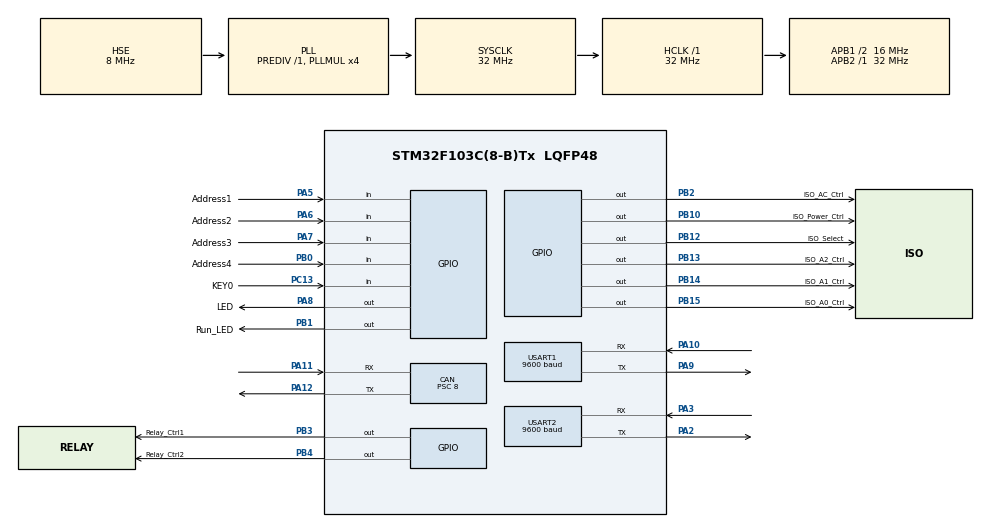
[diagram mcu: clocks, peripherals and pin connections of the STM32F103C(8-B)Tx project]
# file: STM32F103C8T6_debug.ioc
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CAN.AWUM=ENABLE
CAN.BS1=CAN_BS1_6TQ
CAN.CalculateBaudRate=250000
CAN.CalculateTimeBit=4000
CAN.CalculateTimeQuantum=500.0
CAN.NART=ENABLE
CAN.Prescaler=8
Dma.Request0=USART1_RX
Dma.Request1=USART1_TX
Dma.Request2=USART2_TX
Dma.USART1_RX.0.Direction=DMA_PERIPH_TO_MEMORY
Dma.USART1_RX.0.Instance=DMA1_Channel5
Dma.USART1_RX.0.MemDataAlignment=DMA_MDATAALIGN_BYTE
Dma.USART1_RX.0.MemInc=DMA_MINC_ENABLE
Dma.USART1_RX.0.Mode=DMA_NORMAL
Dma.USART1_RX.0.PeriphDataAlignment=DMA_PDATAALIGN_BYTE
Dma.USART1_RX.0.PeriphInc=DMA_PINC_DISABLE
Dma.USART1_RX.0.Priority=DMA_PRIORITY_LOW
Dma.USART1_TX.1.Direction=DMA_MEMORY_TO_PERIPH
Dma.USART1_TX.1.Instance=DMA1_Channel4
Dma.USART1_TX.1.MemDataAlignment=DMA_MDATAALIGN_BYTE
Dma.USART1_TX.1.MemInc=DMA_MINC_ENABLE
Dma.USART1_TX.1.Mode=DMA_NORMAL
Dma.USART1_TX.1.PeriphDataAlignment=DMA_PDATAALIGN_BYTE
Dma.USART1_TX.1.PeriphInc=DMA_PINC_DISABLE
Dma.USART1_TX.1.Priority=DMA_PRIORITY_LOW
Dma.USART2_TX.2.Direction=DMA_MEMORY_TO_PERIPH
Dma.USART2_TX.2.Instance=DMA1_Channel7
Dma.USART2_TX.2.MemDataAlignment=DMA_MDATAALIGN_BYTE
Dma.USART2_TX.2.MemInc=DMA_MINC_ENABLE
Dma.USART2_TX.2.Mode=DMA_NORMAL
Dma.USART2_TX.2.PeriphDataAlignment=DMA_PDATAALIGN_BYTE
Dma.USART2_TX.2.PeriphInc=DMA_PINC_DISABLE
Dma.USART2_TX.2.Priority=DMA_PRIORITY_LOW
FREERTOS.Tasks01=defaultTask,24,128,StartDefaultTask,Default,NULL,Dynamic,NULL,NULL;BSP_Task1,8,128,BSP_Task,As weak,NULL,Dynamic,NULL,NULL;APL_Task1,8,512,APL_Task,As weak,NULL,Dynamic,NULL,NULL;CAN_Task1,8,256,CAN_Task,As weak,NULL,Dynamic,NULL,NULL
FREERTOS.configTOTAL_HEAP_SIZE=5120
IWDG.Prescaler=IWDG_PRESCALER_32
IWDG.Reload=2500
Mcu.Family=STM32F1
Mcu.Name=STM32F103C(8-B)Tx
Mcu.Package=LQFP48
NVIC.DMA1_Channel4_IRQn=true\:5\:0\:false\:false\:true\:true\:false\:true
NVIC.DMA1_Channel5_IRQn=true\:5\:0\:false\:false\:true\:true\:false\:true
NVIC.DMA1_Channel7_IRQn=true\:5\:0\:false\:false\:true\:true\:false\:true
NVIC.PriorityGroup=NVIC_PRIORITYGROUP_4
NVIC.TIM1_UP_IRQn=true\:5\:0\:true\:false\:true\:true\:true\:true
NVIC.USART1_IRQn=true\:5\:0\:false\:false\:true\:true\:true\:true
NVIC.USART2_IRQn=true\:5\:0\:false\:false\:true\:true\:true\:true
NVIC.USB_LP_CAN1_RX0_IRQn=true\:5\:0\:false\:false\:true\:true\:true\:true
PA10.Mode=Asynchronous
PA10.Signal=USART1_RX
PA11.Mode=CAN_Activate
PA11.Signal=CAN_RX
PA12.Mode=CAN_Activate
PA12.Signal=CAN_TX
PA13.Mode=Serial_Wire
PA13.Signal=SYS_JTMS-SWDIO
PA14.Mode=Serial_Wire
PA14.Signal=SYS_JTCK-SWCLK
PA2.Mode=Asynchronous
PA2.Signal=USART2_TX
PA3.Mode=Asynchronous
PA3.Signal=USART2_RX
PA5.GPIO_Label=Address1
PA5.Signal=GPIO_Input
PA6.GPIO_Label=Address2
PA6.Signal=GPIO_Input
PA7.GPIO_Label=Address3
PA7.Signal=GPIO_Input
PA8.GPIO_Label=LED
PA8.Signal=GPIO_Output
PA9.Mode=Asynchronous
PA9.Signal=USART1_TX
PB0.GPIO_Label=Address4
PB0.Signal=GPIO_Input
PB1.GPIO_Label=Run_LED
PB1.Signal=GPIO_Output
PB10.GPIO_Label=ISO_Power_Ctrl
PB10.Signal=GPIO_Output
PB12.GPIO_Label=ISO_Select
PB12.Signal=GPIO_Output
PB13.GPIO_Label=ISO_A2_Ctrl
PB13.Signal=GPIO_Output
PB14.GPIO_Label=ISO_A1_Ctrl
PB14.Signal=GPIO_Output
PB15.GPIO_Label=ISO_A0_Ctrl
PB15.Signal=GPIO_Output
PB2.GPIO_Label=ISO_AC_Ctrl
PB2.Signal=GPIO_Output
PB3.GPIO_Label=Relay_Ctrl1
PB3.Signal=GPIO_Output
PB4.GPIO_Label=Relay_Ctrl2
PB4.Signal=GPIO_Output
PC13-TAMPER-RTC.GPIO_Label=KEY0
PC13-TAMPER-RTC.Signal=GPIO_Input
PD0-OSC_IN.Mode=HSE-External-Oscillator
PD0-OSC_IN.Signal=RCC_OSC_IN
PD1-OSC_OUT.Mode=HSE-External-Oscillator
PD1-OSC_OUT.Signal=RCC_OSC_OUT
ProjectManager.HeapSize=0x200
ProjectManager.StackSize=0x400
ProjectManager.TargetToolchain=MDK-ARM V5.32
RCC.AHBFreq_Value=32000000
RCC.APB1CLKDivider=RCC_HCLK_DIV2
RCC.APB1Freq_Value=16000000
RCC.APB1TimFreq_Value=32000000
RCC.APB2Freq_Value=32000000
RCC.APB2TimFreq_Value=32000000
RCC.HCLKFreq_Value=32000000
RCC.PLLMUL=RCC_PLL_MUL4
RCC.PLLSourceVirtual=RCC_PLLSOURCE_HSE
RCC.SYSCLKFreq_VALUE=32000000
RCC.SYSCLKSource=RCC_SYSCLKSOURCE_PLLCLK
RCC.USBFreq_Value=32000000
TIM1.AutoReloadPreload=TIM_AUTORELOAD_PRELOAD_ENABLE
TIM1.Period=9
TIM1.Prescaler=3199
USART1.BaudRate=9600
USART1.VirtualMode=VM_ASYNC
USART2.BaudRate=9600
USART2.VirtualMode=VM_ASYNC
VP_FREERTOS_VS_CMSIS_V2.Mode=CMSIS_V2
VP_IWDG_VS_IWDG.Mode=IWDG_Activate
VP_TIM1_VS_ClockSourceINT.Mode=Internal
board=custom

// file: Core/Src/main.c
/* USER CODE BEGIN Header */
/**
  ******************************************************************************
  * @file           : main.c
  * @brief          : Main program body
  ******************************************************************************
  * @attention
  *
  * Copyright (c) 2026 STMicroelectronics.
  * All rights reserved.
  *
  * This software is licensed under terms that can be found in the LICENSE file
  * in the root directory of this software component.
  * If no LICENSE file comes with this software, it is provided AS-IS.
  *
  ******************************************************************************
  */
/* USER CODE END Header */
#include "main.h"
#include "cmsis_os.h"
#include "can.h"
#include "dma.h"
#include "iwdg.h"
#include "tim.h"
#include "usart.h"
#include "gpio.h"

void SystemClock_Config(void);
void MX_FREERTOS_Init(void);

int main(void)
{

  /* MCU Configuration--------------------------------------------------------*/

  /* Reset of all peripherals, Initializes the Flash interface and the Systick. */
  HAL_Init();

  /* Configure the system clock */
  SystemClock_Config();

  /* Initialize all configured peripherals */
  MX_GPIO_Init();
  MX_CAN_Init();
  MX_DMA_Init();
  MX_USART1_UART_Init();
  MX_TIM1_Init();
  MX_USART2_UART_Init();
//  MX_IWDG_Init();

  /* Init scheduler */
  osKernelInitialize();  /* Call init function for freertos objects (in freertos.c) */
  MX_FREERTOS_Init();
  /* Start scheduler */
  osKernelStart();

  /* We should never get here as control is now taken by the scheduler */
  /* Infinite loop */
  while (1)
  {

  }
}

void SystemClock_Config(void)
{
  RCC_OscInitTypeDef RCC_OscInitStruct = {0};
  RCC_ClkInitTypeDef RCC_ClkInitStruct = {0};

  /** Initializes the RCC Oscillators according to the specified parameters
  * in the RCC_OscInitTypeDef structure.
  */
  RCC_OscInitStruct.OscillatorType = RCC_OSCILLATORTYPE_LSI|RCC_OSCILLATORTYPE_HSE;
  RCC_OscInitStruct.HSEState = RCC_HSE_ON;
  RCC_OscInitStruct.HSEPredivValue = RCC_HSE_PREDIV_DIV1;
  RCC_OscInitStruct.HSIState = RCC_HSI_ON;
  RCC_OscInitStruct.LSIState = RCC_LSI_ON;
  RCC_OscInitStruct.PLL.PLLState = RCC_PLL_ON;
  RCC_OscInitStruct.PLL.PLLSource = RCC_PLLSOURCE_HSE;
  RCC_OscInitStruct.PLL.PLLMUL = RCC_PLL_MUL4;
  if (HAL_RCC_OscConfig(&RCC_OscInitStruct) != HAL_OK)
  {
    Error_Handler();
  }
  /** Initializes the CPU, AHB and APB buses clocks
  */
  RCC_ClkInitStruct.ClockType = RCC_CLOCKTYPE_HCLK|RCC_CLOCKTYPE_SYSCLK
                              |RCC_CLOCKTYPE_PCLK1|RCC_CLOCKTYPE_PCLK2;
  RCC_ClkInitStruct.SYSCLKSource = RCC_SYSCLKSOURCE_PLLCLK;
  RCC_ClkInitStruct.AHBCLKDivider = RCC_SYSCLK_DIV1;
  RCC_ClkInitStruct.APB1CLKDivider = RCC_HCLK_DIV2;
  RCC_ClkInitStruct.APB2CLKDivider = RCC_HCLK_DIV1;

  if (HAL_RCC_ClockConfig(&RCC_ClkInitStruct, FLASH_LATENCY_1) != HAL_OK)
  {
    Error_Handler();
  }
}

void Error_Handler(void)
{
  __disable_irq();
  while (1)
  {
  }
}

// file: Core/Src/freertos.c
/* USER CODE BEGIN Header */
/**
  ******************************************************************************
  * File Name          : freertos.c
  * Description        : Code for freertos applications
  ******************************************************************************
  * @attention
  *
  * Copyright (c) 2026 STMicroelectronics.
  * All rights reserved.
  *
  * This software is licensed under terms that can be found in the LICENSE file
  * in the root directory of this software component.
  * If no LICENSE file comes with this software, it is provided AS-IS.
  *
  ******************************************************************************
  */
/* USER CODE END Header */

#include "FreeRTOS.h"
#include "task.h"
#include "main.h"
#include "cmsis_os.h"

/* USER CODE BEGIN Includes */
#include "device_control.h"
#include "share_data.h"
/* USER CODE END Includes */

/* Definitions for defaultTask */
osThreadId_t defaultTaskHandle;
const osThreadAttr_t defaultTask_attributes = {
  .name = "defaultTask",
  .stack_size = 128 * 4,
  .priority = (osPriority_t) osPriorityNormal,
};
/* Definitions for BSP_Task1 */
osThreadId_t BSP_Task1Handle;
const osThreadAttr_t BSP_Task1_attributes = {
  .name = "BSP_Task1",
  .stack_size = 128 * 4,
  .priority = (osPriority_t) osPriorityLow,
};
/* Definitions for APL_Task1 */
osThreadId_t APL_Task1Handle;
const osThreadAttr_t APL_Task1_attributes = {
  .name = "APL_Task1",
  .stack_size = 256 * 4,
  .priority = (osPriority_t) osPriorityLow,
};
/* Definitions for CAN_Task1 */
osThreadId_t CAN_Task1Handle;
const osThreadAttr_t CAN_Task1_attributes = {
  .name = "CAN_Task1",
  .stack_size = 256 * 4,
  .priority = (osPriority_t) osPriorityLow,
};

void StartDefaultTask(void *argument);
void BSP_Task(void *argument);
void APL_Task(void *argument);
void CAN_Task(void *argument);

void MX_FREERTOS_Init(void); /* (MISRA C 2004 rule 8.1) */

void MX_FREERTOS_Init(void) {

  /* Create the thread(s) */
  /* creation of defaultTask */
  defaultTaskHandle = osThreadNew(StartDefaultTask, NULL, &defaultTask_attributes);

  /* creation of BSP_Task1 */
  BSP_Task1Handle = osThreadNew(BSP_Task, NULL, &BSP_Task1_attributes);

  /* creation of APL_Task1 */
  APL_Task1Handle = osThreadNew(APL_Task, NULL, &APL_Task1_attributes);

  /* creation of CAN_Task1 */
  CAN_Task1Handle = osThreadNew(CAN_Task, NULL, &CAN_Task1_attributes);

  /* USER CODE BEGIN RTOS_EVENTS */
  /* add events, ... */

//  device_control(DEV_TYPE_UART, "usart1", DEV_CTRL_OPEN, &huart1_cotent);
    share_data_init(CCU_V1);

  /* USER CODE END RTOS_EVENTS */

}

void StartDefaultTask(void *argument)
{
  for(;;)
  {
    osDelay(1);
  }
}

__weak void BSP_Task(void *argument)
{
  for(;;)
  {
    osDelay(1);
  }
}

__weak void APL_Task(void *argument)
{
  for(;;)
  {
    osDelay(1);
  }
}

__weak void CAN_Task(void *argument)
{
  for(;;)
  {
    osDelay(1);
  }
}
